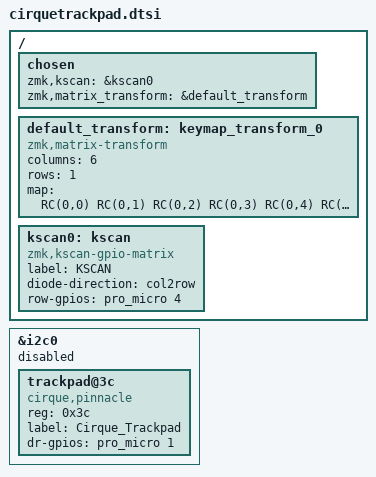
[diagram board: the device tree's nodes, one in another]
#include <dt-bindings/zmk/matrix_transform.h>

/ {
    chosen {
        zmk,kscan = &kscan0;
		zmk,matrix_transform = &default_transform;
    };

    default_transform: keymap_transform_0 {
		compatible = "zmk,matrix-transform";
		columns = <6>;
		rows = <1>;
		map = <
RC(0,0) RC(0,1) RC(0,2) RC(0,3) RC(0,4) RC(0,5)
	  >;
	};

    kscan0: kscan {
        compatible = "zmk,kscan-gpio-matrix";
        label = "KSCAN";

        diode-direction = "col2row";
        row-gpios
           = <&pro_micro 4 (GPIO_ACTIVE_HIGH | GPIO_PULL_DOWN)>
           ;
	};
};

&i2c0 {
	status = "disabled";    
        trackpad@3c {
		compatible = "cirque,pinnacle";
		reg = <0x3c>;
		label = "Cirque_Trackpad";
        dr-gpios = <&pro_micro 1 GPIO_ACTIVE_HIGH>;
	    //rotate-90;
	    //sleep;
	    //no-taps;
    };
  };

